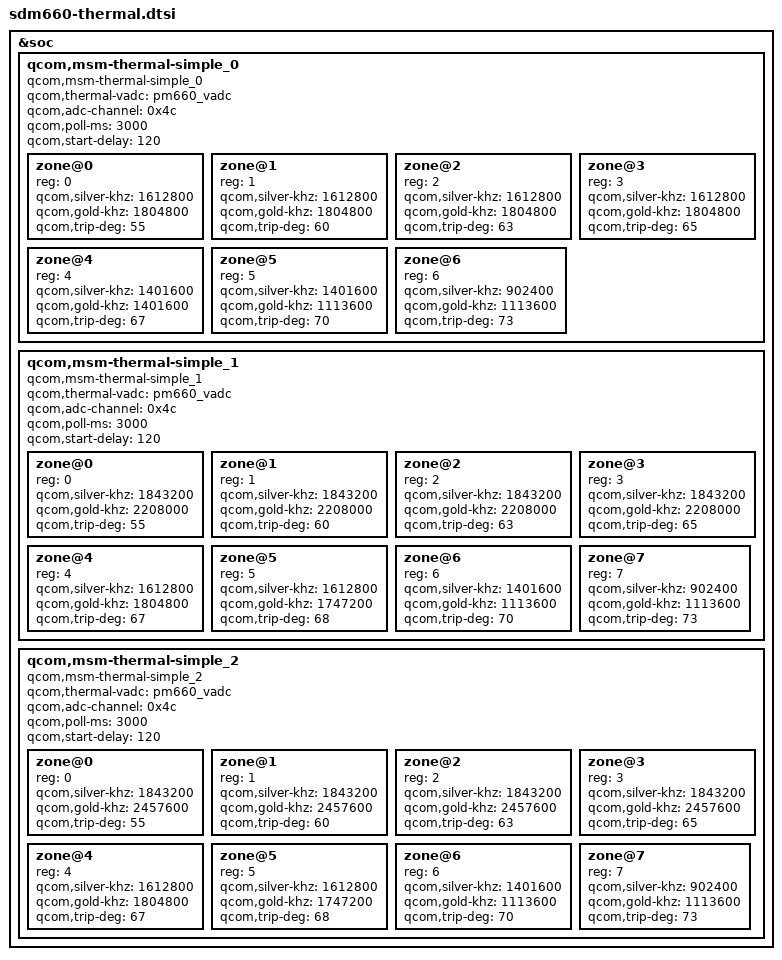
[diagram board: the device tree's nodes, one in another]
/* Copyright (c) 2016-2019, The Linux Foundation. All rights reserved.
 *
 * This program is free software; you can redistribute it and/or modify
 * it under the terms of the GNU General Public License version 2 and
 * only version 2 as published by the Free Software Foundation.
 *
 * This program is distributed in the hope that it will be useful,
 * but WITHOUT ANY WARRANTY; without even the implied warranty of
 * MERCHANTABILITY or FITNESS FOR A PARTICULAR PURPOSE.  See the
 * GNU General Public License for more details.
 */

&soc {
	/* (1.6 GHz small 1.8 GHz big) SDM636 NON-OC */
	qcom,msm-thermal-simple_0 {
		#address-cells = <1>;
		#size-cells = <0>;
		compatible = "qcom,msm-thermal-simple_0";
		qcom,thermal-vadc = <&pm660_vadc>;
		qcom,adc-channel = <0x4c>;
		qcom,poll-ms = <3000>;
		qcom,start-delay = <120>;
		zone@0 {
			reg = <0>;
			qcom,silver-khz = <1612800>;
			qcom,gold-khz = <1804800>;
			qcom,trip-deg = <55>;
		};

		zone@1 {
			reg = <1>;
			qcom,silver-khz = <1612800>;
			qcom,gold-khz = <1804800>;
			qcom,trip-deg = <60>;
		};

		zone@2 {
			reg = <2>;
			qcom,silver-khz = <1612800>;
			qcom,gold-khz = <1804800>;
			qcom,trip-deg = <63>;
		};

		zone@3 {
			reg = <3>;
			qcom,silver-khz = <1612800>;
			qcom,gold-khz = <1804800>;
			qcom,trip-deg = <65>;
		};

		zone@4 {
			reg = <4>;
			qcom,silver-khz = <1401600>;
			qcom,gold-khz = <1401600>;
			qcom,trip-deg = <67>;
		};

		zone@5 {
			reg = <5>;
			qcom,silver-khz = <1401600>;
			qcom,gold-khz = <1113600>;
			qcom,trip-deg = <70>;
		};

		zone@6 {
			reg = <6>;
			qcom,silver-khz = <902400>;
			qcom,gold-khz = <1113600>;
			qcom,trip-deg = <73>;
		};
	};


	/* (1.8 GHz small 2.2 GHz big) SDM636-2.2-OC / SDM660-NON_OC */
	qcom,msm-thermal-simple_1 {
		#address-cells = <1>;
		#size-cells = <0>;
		compatible = "qcom,msm-thermal-simple_1";
		qcom,thermal-vadc = <&pm660_vadc>;
		qcom,adc-channel = <0x4c>;
		qcom,poll-ms = <3000>;
		qcom,start-delay = <120>;
		zone@0 {
			reg = <0>;
			qcom,silver-khz = <1843200>;
			qcom,gold-khz = <2208000>;
			qcom,trip-deg = <55>;
		};

		zone@1 {
			reg = <1>;
			qcom,silver-khz = <1843200>;
			qcom,gold-khz = <2208000>;
			qcom,trip-deg = <60>;
		};

		zone@2 {
			reg = <2>;
			qcom,silver-khz = <1843200>;
			qcom,gold-khz = <2208000>;
			qcom,trip-deg = <63>;
		};

		zone@3 {
			reg = <3>;
			qcom,silver-khz = <1843200>;
			qcom,gold-khz = <2208000>;
			qcom,trip-deg = <65>;
		};

		zone@4 {
			reg = <4>;
			qcom,silver-khz = <1612800>;
			qcom,gold-khz = <1804800>;
			qcom,trip-deg = <67>;
		};

		zone@5 {
			reg = <5>;
			qcom,silver-khz = <1612800>;
			qcom,gold-khz = <1747200>;
			qcom,trip-deg = <68>;
		};

		zone@6 {
			reg = <6>;
			qcom,silver-khz = <1401600>;
			qcom,gold-khz = <1113600>;
			qcom,trip-deg = <70>;
		};

		zone@7 {
			reg = <7>;
			qcom,silver-khz = <902400>;
			qcom,gold-khz = <1113600>;
			qcom,trip-deg = <73>;
		};
	};

	/* 2.4-OC (1.8 GHz small 2.4 GHz big) */
	qcom,msm-thermal-simple_2 {
		#address-cells = <1>;
		#size-cells = <0>;
		compatible = "qcom,msm-thermal-simple_2";
		qcom,thermal-vadc = <&pm660_vadc>;
		qcom,adc-channel = <0x4c>;
		qcom,poll-ms = <3000>;
		qcom,start-delay = <120>;
		zone@0 {
			reg = <0>;
			qcom,silver-khz = <1843200>;
			qcom,gold-khz = <2457600>;
			qcom,trip-deg = <55>;
		};

		zone@1 {
			reg = <1>;
			qcom,silver-khz = <1843200>;
			qcom,gold-khz = <2457600>;
			qcom,trip-deg = <60>;
		};

		zone@2 {
			reg = <2>;
			qcom,silver-khz = <1843200>;
			qcom,gold-khz = <2457600>;
			qcom,trip-deg = <63>;
		};

		zone@3 {
			reg = <3>;
			qcom,silver-khz = <1843200>;
			qcom,gold-khz = <2457600>;
			qcom,trip-deg = <65>;
		};

		zone@4 {
			reg = <4>;
			qcom,silver-khz = <1612800>;
			qcom,gold-khz = <1804800>;
			qcom,trip-deg = <67>;
		};

		zone@5 {
			reg = <5>;
			qcom,silver-khz = <1612800>;
			qcom,gold-khz = <1747200>;
			qcom,trip-deg = <68>;
		};

		zone@6 {
			reg = <6>;
			qcom,silver-khz = <1401600>;
			qcom,gold-khz = <1113600>;
			qcom,trip-deg = <70>;
		};

		zone@7 {
			reg = <7>;
			qcom,silver-khz = <902400>;
			qcom,gold-khz = <1113600>;
			qcom,trip-deg = <73>;
		};
	};
};
